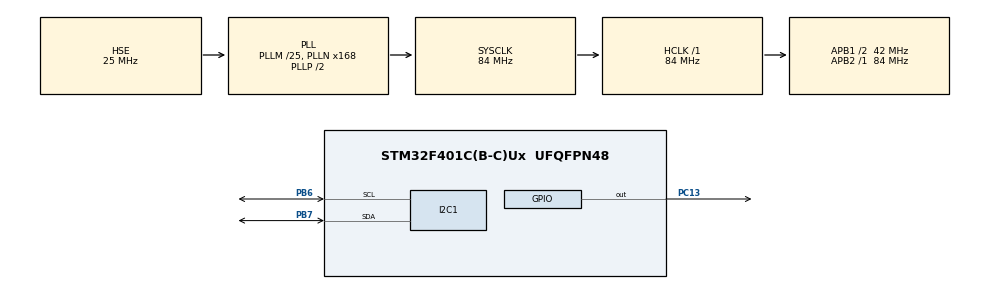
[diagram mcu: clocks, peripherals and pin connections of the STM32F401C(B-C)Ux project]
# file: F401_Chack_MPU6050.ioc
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Mcu.Family=STM32F4
RCC.PLLSourceVirtual=RCC_PLLSOURCE_HSE
RCC.CortexFreq_Value=84000000
PH1\ -\ OSC_OUT.Mode=HSE-External-Oscillator
RCC.APB1CLKDivider=RCC_HCLK_DIV2
PC13-ANTI_TAMP.PinState=GPIO_PIN_RESET
RCC.SYSCLKSource=RCC_SYSCLKSOURCE_PLLCLK
ProjectManager.StackSize=0x400
PA13.Signal=SYS_JTMS-SWDIO
PH0\ -\ OSC_IN.Mode=HSE-External-Oscillator
PH0\ -\ OSC_IN.Signal=RCC_OSC_IN
ProjectManager.TargetToolchain=STM32CubeIDE
I2C1.I2C_Mode=I2C_Fast
RCC.HCLKFreq_Value=84000000
RCC.APB2TimFreq_Value=84000000
PB6.Signal=I2C1_SCL
PB6.Mode=I2C
RCC.LSE_VALUE=32768
RCC.AHBFreq_Value=84000000
RCC.HSE_VALUE=25000000
PH1\ -\ OSC_OUT.Signal=RCC_OSC_OUT
board=custom
PC13-ANTI_TAMP.Signal=GPIO_Output
RCC.VCOOutputFreq_Value=168000000
RCC.APB2Freq_Value=84000000
PA14.Mode=Serial_Wire
PB7.Signal=I2C1_SDA
PA13.Mode=Serial_Wire
Mcu.Name=STM32F401C(B-C)Ux
RCC.48MHZClocksFreq_Value=42000000
RCC.SYSCLKFreq_VALUE=84000000
Mcu.Package=UFQFPN48
PB7.Mode=I2C
PA14.Signal=SYS_JTCK-SWCLK
ProjectManager.HeapSize=0x200
RCC.HSI_VALUE=16000000
NVIC.PriorityGroup=NVIC_PRIORITYGROUP_4
RCC.PLLM=25
RCC.PLLN=168
RCC.APB1TimFreq_Value=84000000
RCC.APB1Freq_Value=42000000

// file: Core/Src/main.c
/* USER CODE BEGIN Header */
/**
  ******************************************************************************
  * @file           : main.c
  * @brief          : Main program body
  ******************************************************************************
  * @attention
  *
  * <h2><center>&copy; Copyright (c) 2023 STMicroelectronics.
  * All rights reserved.</center></h2>
  *
  * This software component is licensed by ST under BSD 3-Clause license,
  * the "License"; You may not use this file except in compliance with the
  * License. You may obtain a copy of the License at:
  *                        opensource.org/licenses/BSD-3-Clause
  *
  ******************************************************************************
  */
/* USER CODE END Header */
#include "main.h"
#include "i2c.h"
#include "gpio.h"

/* USER CODE BEGIN PV */

	uint8_t check;

/* USER CODE END PV */

void SystemClock_Config(void);

int main(void)
{

  /* MCU Configuration--------------------------------------------------------*/

  /* Reset of all peripherals, Initializes the Flash interface and the Systick. */
  HAL_Init();

  /* Configure the system clock */
  SystemClock_Config();

  /* Initialize all configured peripherals */
  MX_GPIO_Init();
  MX_I2C1_Init();
  /* USER CODE BEGIN 2 */

  	  /* DATA CHECK MUP6050 */

		  HAL_I2C_Mem_Read(&hi2c1, 0xD0, 0x75, 1, &check, 1, 100);
		  HAL_Delay(100);

//  HAL_I2C_Mem_Read(&hi2c1, 0xD0, 0x75, 1, &check_ID, 1, 100);
//  HAL_I2C_Mem_Write(&hi2c1, 0xD0, 0x6B, 1, (uint8_t*) 0x00, 1, 100);
//  HAL_Delay(100);

  /* USER CODE END 2 */

  /* Infinite loop */
  while (1)
  {

    /* USER CODE BEGIN 3 */

	    /* TOGGLE PIN LED AFTER MPU CHECK */

		  HAL_GPIO_TogglePin(GPIOC, GPIO_PIN_13);
		  HAL_Delay(100);

  }
  /* USER CODE END 3 */
}

void SystemClock_Config(void)
{
  RCC_OscInitTypeDef RCC_OscInitStruct = {0};
  RCC_ClkInitTypeDef RCC_ClkInitStruct = {0};

  /** Configure the main internal regulator output voltage
  */
  __HAL_RCC_PWR_CLK_ENABLE();
  __HAL_PWR_VOLTAGESCALING_CONFIG(PWR_REGULATOR_VOLTAGE_SCALE2);
  /** Initializes the RCC Oscillators according to the specified parameters
  * in the RCC_OscInitTypeDef structure.
  */
  RCC_OscInitStruct.OscillatorType = RCC_OSCILLATORTYPE_HSE;
  RCC_OscInitStruct.HSEState = RCC_HSE_ON;
  RCC_OscInitStruct.PLL.PLLState = RCC_PLL_ON;
  RCC_OscInitStruct.PLL.PLLSource = RCC_PLLSOURCE_HSE;
  RCC_OscInitStruct.PLL.PLLM = 25;
  RCC_OscInitStruct.PLL.PLLN = 168;
  RCC_OscInitStruct.PLL.PLLP = RCC_PLLP_DIV2;
  RCC_OscInitStruct.PLL.PLLQ = 4;
  if (HAL_RCC_OscConfig(&RCC_OscInitStruct) != HAL_OK)
  {
    Error_Handler();
  }
  /** Initializes the CPU, AHB and APB buses clocks
  */
  RCC_ClkInitStruct.ClockType = RCC_CLOCKTYPE_HCLK|RCC_CLOCKTYPE_SYSCLK
                              |RCC_CLOCKTYPE_PCLK1|RCC_CLOCKTYPE_PCLK2;
  RCC_ClkInitStruct.SYSCLKSource = RCC_SYSCLKSOURCE_PLLCLK;
  RCC_ClkInitStruct.AHBCLKDivider = RCC_SYSCLK_DIV1;
  RCC_ClkInitStruct.APB1CLKDivider = RCC_HCLK_DIV2;
  RCC_ClkInitStruct.APB2CLKDivider = RCC_HCLK_DIV1;

  if (HAL_RCC_ClockConfig(&RCC_ClkInitStruct, FLASH_LATENCY_2) != HAL_OK)
  {
    Error_Handler();
  }
}

void Error_Handler(void)
{
  __disable_irq();
  while (1)
  {
  }
}

/************************ (C) COPYRIGHT STMicroelectronics *****END OF FILE****/
